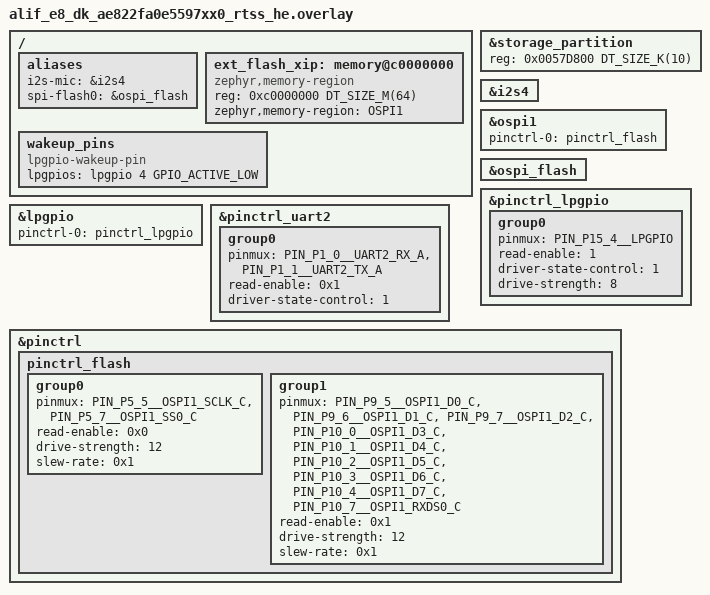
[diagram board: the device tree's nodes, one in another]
/* Copyright (C) Alif Semiconductor - All Rights Reserved.
 * Use, distribution and modification of this code is permitted under the
 * terms stated in the Alif Semiconductor Software License Agreement
 *
 * You should have received a copy of the Alif Semiconductor Software
 * License Agreement with this file. If not, please write to:
 * contact@alifsemi.com, or visit: https: //alifsemi.com/license
 *
 */

 #include "common.overlay"

/ {
	aliases {
		i2s-mic = &i2s4;
		spi-flash0 = &ospi_flash;
	};
};

/*
 * This is a large (~4.5 MB) single-image, non-MCUBoot application. In non-MCUBoot
 * builds the executable MRAM MPU region (soc/alif/ensemble mpu_regions.c) spans
 * boot_partition..storage_partition, so the code that may be executed ends where
 * the storage partition begins. The default layout places storage at 0x1A0000,
 * capping executable MRAM at ~1.62 MB and causing an Instruction Access Violation
 * as soon as code above that boundary runs. Move storage to the top of MRAM so
 * the executable region covers the whole image.
 */
&storage_partition {
	reg = <0x0057D800 DT_SIZE_K(10)>;
};

&i2s4 {
	status = "okay";
};

/ {
	ext_flash_xip: memory@c0000000 {
		compatible = "zephyr,memory-region";
		reg = <0xc0000000 DT_SIZE_M(64)>;
		zephyr,memory-region = "OSPI1";
	};
};

&ospi1 {
	pinctrl-0 = <&pinctrl_flash>;
	status = "okay";
};

&ospi_flash {
	status = "okay";
};

&pinctrl_lpgpio {
	group0 {
		pinmux = <PIN_P15_4__LPGPIO>;
		read-enable = <1>;
		driver-state-control = <1>;
		drive-strength = <8>;
	};
};

&lpgpio {
	pinctrl-0 = < &pinctrl_lpgpio >;
	pinctrl-names = "default";
	status = "okay";
};

/ {
	wakeup_pins: wakeup_pins {
		compatible = "lpgpio-wakeup-pin";
		lpgpios = <&lpgpio 4 GPIO_ACTIVE_LOW>;
	};
};

&pinctrl_uart2 {
	group0 {
		pinmux = <PIN_P1_0__UART2_RX_A>,
				 <PIN_P1_1__UART2_TX_A>;
		read-enable = <0x1>;
		driver-state-control = <1>; /* pull-up: initialize RX active-high */
	};
};

&pinctrl {
	pinctrl_flash:pinctrl_flash {
		group0 {
			pinmux = <PIN_P5_5__OSPI1_SCLK_C>,
				 <PIN_P5_7__OSPI1_SS0_C>;
			read-enable = <0x0>;
			drive-strength = <12>;
			slew-rate = <0x1>;
		};
		group1 {
			pinmux = <PIN_P9_5__OSPI1_D0_C>,
				 <PIN_P9_6__OSPI1_D1_C>,
				 <PIN_P9_7__OSPI1_D2_C>,
				 <PIN_P10_0__OSPI1_D3_C>,
				 <PIN_P10_1__OSPI1_D4_C>,
				 <PIN_P10_2__OSPI1_D5_C>,
				 <PIN_P10_3__OSPI1_D6_C>,
				 <PIN_P10_4__OSPI1_D7_C>,
				 <PIN_P10_7__OSPI1_RXDS0_C>;
			read-enable = <0x1>;
			drive-strength = <12>;
			slew-rate = <0x1>;
		};
	};
};
